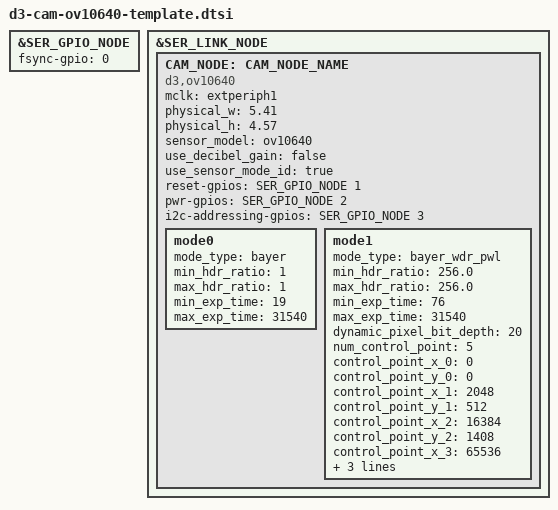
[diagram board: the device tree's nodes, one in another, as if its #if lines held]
/*
 * Copyright (c) 2018-2019, D3 Engineering. All rights reserved.
 *
 * This program is free software; you can redistribute it and/or modify
 * it under the terms of the GNU General Public License as published by
 * the Free Software Foundation; version 2 of the License.
 *
 * This program is distributed in the hope that it will be useful, but WITHOUT
 * ANY WARRANTY; without even the implied warranty of MERCHANTABILITY or
 * FITNESS FOR A PARTICULAR PURPOSE.  See the GNU General Public License for
 * more details.
 */

 #include "d3-reset-cam.dtsi"
 #define CAM_MODEL ov10640
 #define IMG_ADDR_PHYSICAL 32
 #include "d3-cam-common.dtsi"
 #include "d3-check-cam.dtsi"

#define SER_NODE_OVERLAY			\
	gpio-rmten = <0x0>;			\
	gpio-out-src = <0x6>;			\
	gpio-out-en = <0x3>;			\
	gpio-in-en = <0x4>;			\
	hs-clk-div = <2>;			\
	div-m-val = <1>;			\
	div-n-val = <40>;			\
	i2c-voltage-sel = <0x1>;	\
	wait-for-self-configure;

&SER_GPIO_NODE {
	fsync-gpio = <0>;
};

/*
 * The pixel clock is driven from the ub953 serializer board. That
 * board has a 48 Mhz oscillator that is driven through PLLs to
 * provide a clock to the sensor board.
 *
 * The line_length is verified by register 0x3080. If you look
 * *carefully* at the configuration table you'll see it is set to
 * 1480. Please note that it is written twice for an unknown
 * reason. 1480 is the last value written.
 *
 * pixel clock = 77714286 Hz
 * line_length = 1480 clocks
 *
 * Time for a single line: (1/pixel clock) * line_length
 *  (1/77714286) * 1480 == 19 us
 *
 * The maximum exposure time is VTS - 6. VTS is 1666 so the maxmimum
 * exposure time is 1660 lines. This is 31540 us.
 *
 * The minimum exposure time is complicated for HDR mode.
 * The VS min is the minimum very short exposure in rows (0.55 rows).
 *
 *  vs min * row_time * exposure ratio
 *  .55 * 19 us * 256 == 2675.2
 *
 * min exposure rows is 141. We set at 145 lines, or 2755us, to have a
 * little head room. FOR LINEAR MODE, which uses only the Long
 * exposure, the minimum is 1 line or 19 us.
 *
 * 1.5 - 30 gain range
 */

#define OV10640_MODE_COMMON				\
	mclk_khz = "25000";				\
	mclk_multiplier = "22.0";			\
	num_lanes = STR(CSI_LANES);			\
	tegra_sinterface = STR(TEGRA_SINTERFACE);	\
	discontinuous_clk = "no";			\
	dpcm_enable = "false";				\
	cil_settletime = "0";				\
	csi_pixel_bit_depth = "12";			\
	pixel_phase = "bggr";				\
	active_w = "1280";				\
	active_h = "1080";				\
	readout_orientation = "0";			\
	line_length = "1480";				\
	inherent_gain = "1";				\
	serdes_pix_clk_hz = "500000000";		\
	pix_clk_hz = "77714286";			\
	min_framerate = "30";				\
	max_framerate = "30";				\
	embedded_metadata_height = "0";			\
	min_gain_val = "1.5";				\
	max_gain_val = "8.0";				\
	vc_id = STR(PORT_VCID);


&SER_LINK_NODE {
	CAM_NODE: CAM_NODE_NAME {
		compatible = "d3,ov10640";

		mclk = "extperiph1";
		physical_w = "5.41";
		physical_h = "4.57";
		sensor_model = "ov10640";

		use_decibel_gain = "false";
		use_sensor_mode_id = "true";

		// These two properties make GPIO reset logic work
		// These help control the OV10640 reset process more carefully,
		// which alleviates an issue where sensors don't always probe.
		// This is not a perfect fix, but should make it work about 98%
		// of the time.
		reset-gpios = <&SER_GPIO_NODE 1 GPIO_ACTIVE_HIGH>;
		pwr-gpios = <&SER_GPIO_NODE 2 GPIO_ACTIVE_HIGH>;
		i2c-addressing-gpios = <&SER_GPIO_NODE 3 GPIO_ACTIVE_HIGH>;

		/* Long exposure mode (linear) */
		mode0 {
			OV10640_MODE_COMMON
			mode_type = "bayer";
			min_hdr_ratio = "1";
			max_hdr_ratio = "1";
			min_exp_time = "19";
			max_exp_time = "31540";
		};

		/* 3 exposure HDR mode  */
#if D3_OV10640_HDR_ENABLE
		mode1 {
			OV10640_MODE_COMMON
			/* HDR mode specific */
			mode_type = "bayer_wdr_pwl";
			min_hdr_ratio = "256.0";
			max_hdr_ratio = "256.0";
			/* Enforcing a 4 line minimum long exposure time */
			min_exp_time = "76";
			max_exp_time = "31540";
			dynamic_pixel_bit_depth = "20";
			num_control_point = "5";
			control_point_x_0 = "0";
			control_point_y_0 = "0";
			control_point_x_1 = "2048";
			control_point_y_1 = "512";
			control_point_x_2 = "16384";
			control_point_y_2 = "1408";
			control_point_x_3 = "65536";
			control_point_y_3 = "2176";
			control_point_x_4 = "1048576";
			control_point_y_4 = "4096";
		};
#endif /* D3_OV10640_HDR_ENABLE */
	};
};

#include "d3-overlays-cam.dtsi"
